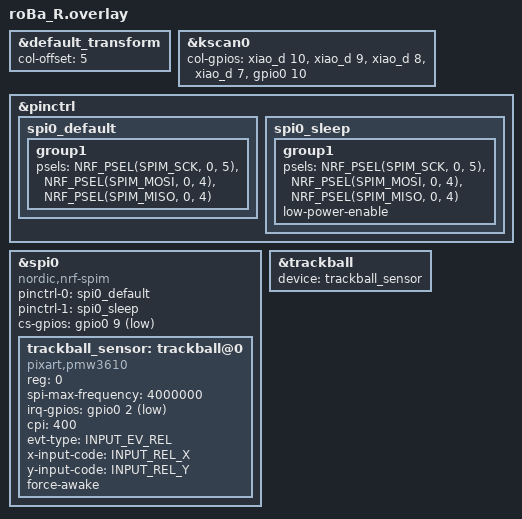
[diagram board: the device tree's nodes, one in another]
#include "roBa.dtsi"

&default_transform {
    col-offset = <5>;
};

&kscan0 {
        col-gpios
            = <&xiao_d 10 GPIO_ACTIVE_HIGH>
            , <&xiao_d 9 GPIO_ACTIVE_HIGH> 
            , <&xiao_d 8 GPIO_ACTIVE_HIGH> 
            , <&xiao_d 7 GPIO_ACTIVE_HIGH> 
            , <&gpio0 10 GPIO_ACTIVE_HIGH>
            ;
};

&pinctrl {
    spi0_default: spi0_default {
        group1 {
            psels = <NRF_PSEL(SPIM_SCK, 0, 5)>,
                <NRF_PSEL(SPIM_MOSI, 0, 4)>, //SDIO
                <NRF_PSEL(SPIM_MISO, 0, 4)>; //SDIO
        };
    };

    spi0_sleep: spi0_sleep {
        group1 {
            psels = <NRF_PSEL(SPIM_SCK, 0, 5)>,
                <NRF_PSEL(SPIM_MOSI, 0, 4)>, //SDIO
                <NRF_PSEL(SPIM_MISO, 0, 4)>; //SDIO
            low-power-enable;
        };
    };
};

#include <zephyr/dt-bindings/input/input-event-codes.h>


&spi0 {
    status = "okay";
    compatible = "nordic,nrf-spim";
    pinctrl-0 = <&spi0_default>;
    pinctrl-1 = <&spi0_sleep>;
    pinctrl-names = "default", "sleep";
    cs-gpios = <&gpio0 9 GPIO_ACTIVE_LOW>;

    trackball_sensor: trackball@0 {
        compatible = "pixart,pmw3610";
        reg = <0>;
        status = "okay";
        spi-max-frequency = <4000000>;
        irq-gpios = <&gpio0 2 (GPIO_ACTIVE_LOW | GPIO_PULL_UP)>;
        cpi = <400>;
        evt-type = <INPUT_EV_REL>;
        x-input-code = <INPUT_REL_X>;
        y-input-code = <INPUT_REL_Y>;
        force-awake;
    };
};

&trackball {
    device = <&trackball_sensor>;
};
